AUTOSAR XML (schema 00046)
package /ComponentTypes
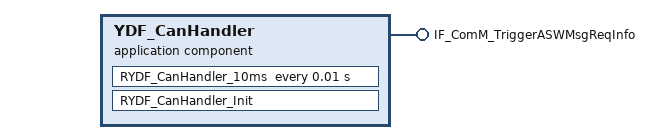
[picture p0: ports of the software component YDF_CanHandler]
  application sw component type YDF_CanHandler
    provide port IF_ComM_TriggerASWMsgReqInfo: nonqueued-sender-com-spec=tec_ComM_TriggerASWMsgReqInfo, provided-interface=IF_ComM_TriggerASWMsgReqInfo
    behavior YDF_CanHandler_InternalBehavior
      init event RYDF_CanHandler_InitEvent: start-on-event=RYDF_CanHandler_Init
      timing event TMT_RYDF_CanHandler_10ms: start-on-event=RYDF_CanHandler_10ms, period=0.01
      runnable RYDF_CanHandler_Init
      runnable RYDF_CanHandler_10ms
        data-send-points:
          access SEND_IF_ComM_TriggerASWMsgReqInfo_tec_ComM_TriggerASWMsgReqInfo: accessed-variable=IF_ComM_TriggerASWMsgReqInfo.tec_ComM_TriggerASWMsgReqInfo
  swc implementation YDF_CanHandler_Implementation: behavior=YDF_CanHandler_InternalBehavior
    code-descriptors:
      code Default: artifact-descriptors=autosar-engineering-object=category=SWSRC
